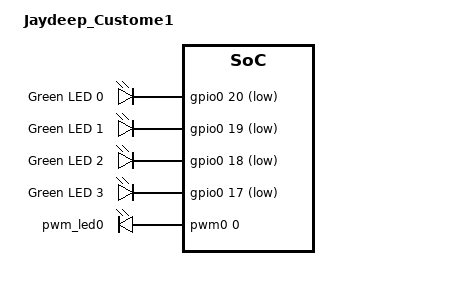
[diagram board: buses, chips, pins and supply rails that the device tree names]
/ {
	model = "Jaydeep_Custome1";
	compatible = "Nordic,Jaydeep-Custom";

	leds {
		compatible = "gpio-leds";
		led0: led_0 {
			gpios = <&gpio0 20 GPIO_ACTIVE_LOW>;
			label = "Green LED 0";
		};
		led1: led_1 {
			gpios = <&gpio0 19 GPIO_ACTIVE_LOW>;
			label = "Green LED 1";
		};
		led2: led_2 {
			gpios = <&gpio0 18 GPIO_ACTIVE_LOW>;
			label = "Green LED 2";
		};
		led3: led_3 {
			gpios = <&gpio0 17 GPIO_ACTIVE_LOW>;
			label = "Green LED 3";
		};
	};


	pwmleds {
		compatible = "pwm-leds";
		pwm_led0: pwm_led_0 {
			pwms = <&pwm0 0 PWM_MSEC(20) PWM_POLARITY_INVERTED>,
				   <&pwm0 1 PWM_MSEC(20) PWM_POLARITY_INVERTED>;
		};
	};

	/* These aliases are provided for compatibility with samples */
	aliases {
		led0 = &led0;
		led1 = &led1;
		led2 = &led2;
		led3 = &led3;
	};
};
